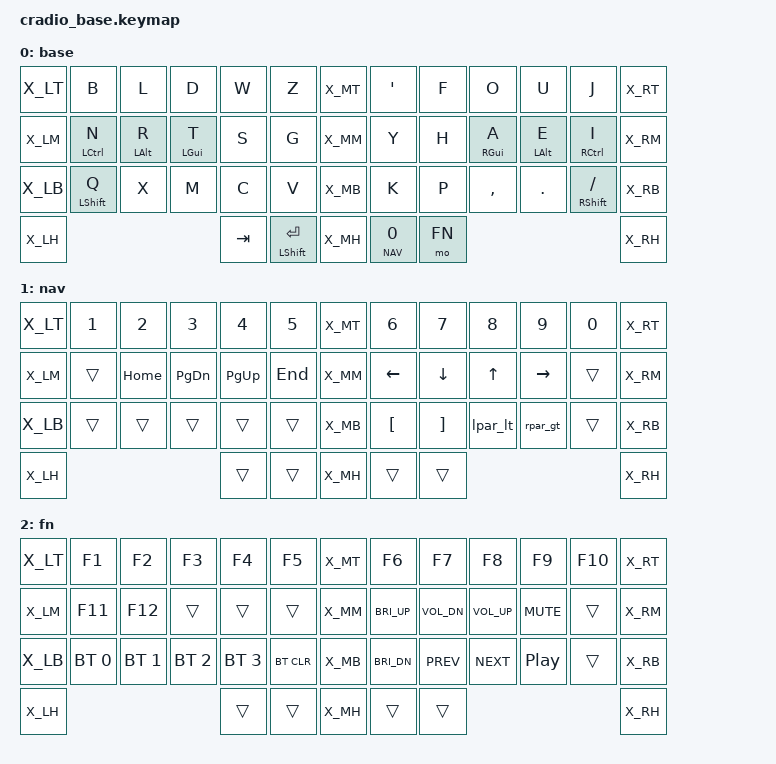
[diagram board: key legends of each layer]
#include <behaviors.dtsi>
#include <behaviors/unicode.dtsi> // requires zmk-unicode module
#include <dt-bindings/zmk/keys.h>
#include <dt-bindings/zmk/bt.h>
#include <dt-bindings/zmk/outputs.h>

#include "zmk-helpers/helper.h"

// Define empty placeholder macros for 34-key layout mapping
#define X_LT
#define X_LM
#define X_LB
#define X_LH
#define X_MT
#define X_MM
#define X_MB
#define X_MH
#define X_RT
#define X_RM
#define X_RB
#define X_RH

#define DEF 0
#define NAV 1
#define FN 2


#define ___ &trans

/* Global settings */

#define QUICK_TAP_MS 175

&sk {  // sticky-key config
    release-after-ms = <900>;  // release after 0.6s
    quick-release;             // no double capitalization when rolling keys
};

&sl {  // sticky-layer config
    ignore-modifiers;          // allow chording sticky mods & layers
};

&lt {  // layer-tap config
    flavor = "balanced";
    tapping-term-ms = <200>;
    quick-tap-ms = <QUICK_TAP_MS>;
};

/* Homerow mods */

#define KEYS_L LT0 LT1 LT2 LT3 LT4 LM0 LM1 LM2 LM3 LM4 LB0 LB1 LB2 LB3 LB4  // left hand
#define KEYS_R RT0 RT1 RT2 RT3 RT4 RM0 RM1 RM2 RM3 RM4 RB0 RB1 RB2 RB3 RB4  // right hand
#undef THUMBS  // undefine first to avoid redefinition warning from key-labels/34.h
#define THUMBS LH1 LH0 RH0 RH1                                      // thumbs

#define MAKE_HRM(NAME, HOLD, TAP, TRIGGER_POS) \
    ZMK_BEHAVIOR(NAME, hold_tap, \
        flavor = "balanced"; \
        tapping-term-ms = <280>; \
        quick-tap-ms = <QUICK_TAP_MS>; \
        require-prior-idle-ms = <150>; \
        bindings = <HOLD>, <TAP>; \
        hold-trigger-key-positions = <TRIGGER_POS>; \
        hold-trigger-on-release; \
    )
MAKE_HRM(hml, &kp, &kp, KEYS_R THUMBS)  // left-hand HRMs
MAKE_HRM(hmr, &kp, &kp, KEYS_L THUMBS)  // right-hand HRMs

#include "cradio_combos.dtsi"  // must be sourced after HRM-combo hack
#include "leader.dtsi"

/* Nav cluster */

// long-tap action on hold, short-tap action on all interrupts
#define MT_CORE \
    flavor = "tap-preferred"; \
    tapping-term-ms = <220>; \
    quick-tap-ms = <220>; \
    hold-trigger-key-positions = <0>;

&mt { MT_CORE };
ZMK_BEHAVIOR(mt_home, hold_tap, bindings = <&masked_home>, <&kp>; MT_CORE)
ZMK_BEHAVIOR(mt_end,  hold_tap,  bindings = <&masked_end>, <&kp>; MT_CORE)

#define NAV_LEFT  &mt_home 0   LEFT    // tap: left  | long-tap: beginning of line
#define NAV_RIGHT &mt_end 0    RIGHT   // tap: right | long-tap: end       of line
#define NAV_UP    &mt LC(HOME) UP      // tap: up    | long-tap: beginning of document
#define NAV_DOWN  &mt LC(END)  DOWN    // tap: down  | long-tap: end       of document

// mask CTRL when holding left/right to avoid accidental jumps to beginning/end of document
#define MASK_MODS(NAME, MODS, BINDING) \
    ZMK_BEHAVIOR(NAME, mod_morph, \
        bindings = <BINDING>, <BINDING>; \
        mods = <MODS>; \
    )
MASK_MODS(masked_home, (MOD_LCTL), &kp HOME)
MASK_MODS(masked_end,  (MOD_LCTL), &kp END)

/* Custom behaviors */

// reuse basic mod-morph scheme
#define SIMPLE_MORPH(NAME, MOD, BINDING1, BINDING2) \
    ZMK_BEHAVIOR(NAME, mod_morph, \
        mods = <(MOD_L ## MOD|MOD_R ## MOD)>; \
        bindings = <BINDING1>, <BINDING2>; \
    )


// tap: left/right parenthesis | shft + tap: less-than/greater-than
SIMPLE_MORPH(lpar_lt, SFT, &kp LPAR, &kp LT)
SIMPLE_MORPH(rpar_gt, SFT, &kp RPAR, &kp GT)

// tap: backspace | shift + tap: delete word (Option + Backspace on macOS)
ZMK_BEHAVIOR(bs_word, mod_morph,
    bindings = <&kp BSPC>, <&kp LA(BSPC)>;
    mods = <(MOD_LSFT|MOD_RSFT)>;
)

// tap: space | shift + tap: dot -> space -> sticky shift | hold: activate layer
ZMK_BEHAVIOR(lt_spc, hold_tap,
    flavor = "balanced";
    tapping-term-ms = <200>;
    quick-tap-ms = <QUICK_TAP_MS>;
    bindings = <&mo>, <&spc_morph>;
)
SIMPLE_MORPH(spc_morph, SFT, &kp SPACE, &dot_spc)
ZMK_BEHAVIOR(dot_spc, macro,
    wait-ms = <0>;
    tap-ms = <5>;
    bindings = <&kp DOT &kp SPACE &sk LSHFT>;
)

/* Keymap */

ZMK_LAYER(base,
//╭──────╮ ╭─────────────┬─────────────┬─────────────┬─────────────┬─────────────╮ ╭──────╮ ╭─────────────┬─────────────┬─────────────┬─────────────┬─────────────╮ ╭──────╮
    X_LT     &kp B         &kp L         &kp D         &kp W         &kp Z           X_MT     &kp SQT       &kp F         &kp O         &kp U         &kp J           X_RT
//├──────┤ ├─────────────┼─────────────┼─────────────┼─────────────┼─────────────┤ ├──────┤ ├─────────────┼─────────────┼─────────────┼─────────────┼─────────────┤ ├──────┤
    X_LM     &hml LCTRL N  &hml LALT R   &hml LGUI T   &kp S         &kp G           X_MM     &kp Y         &kp H         &hmr RGUI A   &hml LALT E   &hmr RCTRL I    X_RM
//├──────┤ ├─────────────┼─────────────┼─────────────┼─────────────┼─────────────┤ ├──────┤ ├─────────────┼─────────────┼─────────────┼─────────────┼─────────────┤ ├──────┤
    X_LB     &hml LSHFT Q  &kp X         &kp M         &kp C         &kp V           X_MB     &kp K         &kp P         &kp COMMA     &kp DOT       &hmr RSHFT FSLH X_RB
//├──────┤ ╰─────────────┼─────────────┴─────────────┼─────────────┼─────────────┤ ├──────┤ ├─────────────┼─────────────┼─────────────┴───────────────────────────╯ ├──────┤
    X_LH                                               &kp TAB       &mt LSHFT RET   X_MH     &lt_spc NAV 0 &mo FN                                                    X_RH
//╰──────╯                                           ╰─────────────┴─────────────╯ ╰──────╯ ╰─────────────┴─────────────╯                                           ╰──────╯
)

ZMK_LAYER(nav,
//╭──────╮ ╭─────────────┬─────────────┬─────────────┬─────────────┬─────────────╮ ╭──────╮ ╭─────────────┬─────────────┬─────────────┬─────────────┬─────────────╮ ╭──────╮
    X_LT     &kp N1        &kp N2        &kp N3        &kp N4        &kp N5          X_MT     &kp N6        &kp N7        &kp N8        &kp N9        &kp N0          X_RT
//├──────┤ ├─────────────┼─────────────┼─────────────┼─────────────┼─────────────┤ ├──────┤ ├─────────────┼─────────────┼─────────────┼─────────────┼─────────────┤ ├──────┤
    X_LM     ___           &kp HOME      &kp PG_DN     &kp PG_UP     &kp END         X_MM     &kp LEFT      &kp DOWN      &kp UP        &kp RIGHT     ___             X_RM
//├──────┤ ├─────────────┼─────────────┼─────────────┼─────────────┼─────────────┤ ├──────┤ ├─────────────┼─────────────┼─────────────┼─────────────┼─────────────┤ ├──────┤
    X_LB     ___           ___           ___           ___           ___             X_MB     &kp LBKT      &kp RBKT      &lpar_lt      &rpar_gt      ___             X_RB
//├──────┤ ╰─────────────┼─────────────┴─────────────┼─────────────┼─────────────┤ ├──────┤ ├─────────────┼─────────────┼─────────────┴───────────────────────────╯ ├──────┤
    X_LH                                               ___           ___             X_MH     ___           ___                                                       X_RH
//╰──────╯                                           ╰─────────────┴─────────────╯ ╰──────╯ ╰─────────────┴─────────────╯                                           ╰──────╯
)

ZMK_LAYER(fn,
//╭──────╮ ╭─────────────┬─────────────┬─────────────┬─────────────┬─────────────╮ ╭──────╮ ╭─────────────┬─────────────┬─────────────┬─────────────┬─────────────╮ ╭──────╮
    X_LT     &kp F1        &kp F2        &kp F3        &kp F4        &kp F5          X_MT     &kp F6        &kp F7        &kp F8        &kp F9        &kp F10         X_RT
//├──────┤ ├─────────────┼─────────────┼─────────────┼─────────────┼─────────────┤ ├──────┤ ├─────────────┼─────────────┼─────────────┼─────────────┼─────────────┤ ├──────┤
    X_LM     &kp F11       &kp F12       ___           ___           ___             X_MM     &kp C_BRI_UP  &kp C_VOL_DN  &kp C_VOL_UP  &kp C_MUTE    ___             X_RM
//├──────┤ ├─────────────┼─────────────┼─────────────┼─────────────┼─────────────┤ ├──────┤ ├─────────────┼─────────────┼─────────────┼─────────────┼─────────────┤ ├──────┤
    X_LB     &bt BT_SEL 0  &bt BT_SEL 1  &bt BT_SEL 2  &bt BT_SEL 3  &bt BT_CLR      X_MB     &kp C_BRI_DN  &kp C_PREV    &kp C_NEXT    &kp C_PP      ___             X_RB
//├──────┤ ╰─────────────┼─────────────┴─────────────┼─────────────┼─────────────┤ ├──────┤ ├─────────────┼─────────────┼─────────────┴───────────────────────────╯ ├──────┤
    X_LH                                               ___           ___             X_MH     ___           ___                                                       X_RH
//╰──────╯                                           ╰─────────────┴─────────────╯ ╰──────╯ ╰─────────────┴─────────────╯                                           ╰──────╯
)

/* vim: set ft=c tw=174: */
